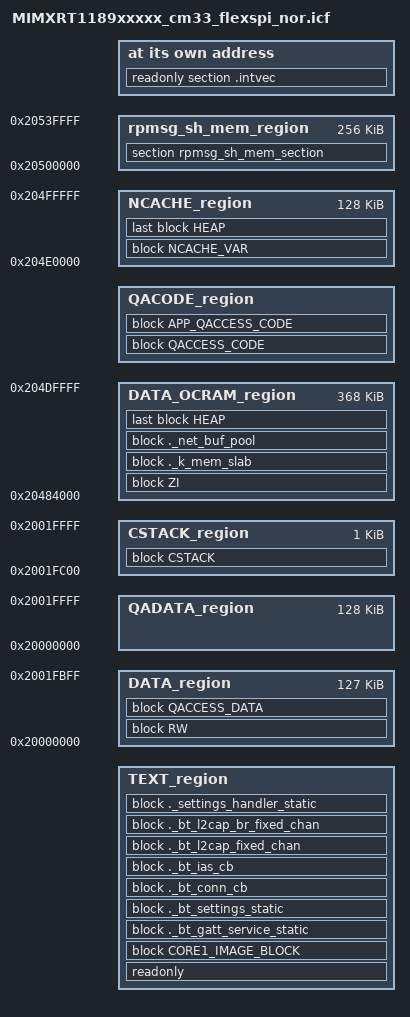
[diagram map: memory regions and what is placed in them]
/*
** ###################################################################
**     Processor:           MIMXRT1189CVM8B_cm33
**     Compiler:            IAR ANSI C/C++ Compiler for ARM
**     Reference manual:    IMXRT1180RM, Rev 2, 12/2022
**     Version:             rev. 0.1, 2021-03-09
**     Build:               b230621
**
**     Abstract:
**         Linker file for the IAR ANSI C/C++ Compiler for ARM
**
**     Copyright 2016 Freescale Semiconductor, Inc.
**     Copyright 2016-2023 NXP
**     SPDX-License-Identifier: BSD-3-Clause
**
**     http:                 www.nxp.com
**     mail:                 support@nxp.com
**
** ###################################################################
*/

/* Board memory map */
define symbol m_code_tcm_start   = 0x0FFE0000;
define symbol m_code_tcm_size    = 0x00020000;
define symbol m_system_tcm_start = 0x20000000;
define symbol m_system_tcm_size  = 0x00020000;
define symbol m_ocram1_start     = 0x20484000;  /* OCRAM1 first 16K access is blocked by TRDC */
define symbol m_ocram1_size      = 0x0007C000;
define symbol m_ocram2_start     = 0x20500000;
define symbol m_ocram2_size      = 0x00040000;

/* CM33 use last 2M bytes space of sdram and hyperram for dual image framework */
define symbol m_sdram_start      = isdefinedsymbol(__dual_image__) ? 0x81E00000 : 0x80000000;
define symbol m_sdram_size       = isdefinedsymbol(__dual_image__) ? 0x00200000 : 0x02000000;
define symbol m_hyperram_start   = isdefinedsymbol(__dual_image__) ? 0x04600000 : 0x04000000;
define symbol m_hyperram_size    = isdefinedsymbol(__dual_image__) ? 0x00200000 : 0x00800000;
define symbol m_flash_start      = 0x28000000;
define symbol m_flash_size       = 0x01000000;

define symbol LITTLEFS_REGION_SIZE = 0x00200000;

define symbol m_core1_image_maximum_size = 0x00040000;

/* General definition */
define symbol app_image_offset         = isdefinedsymbol(__dual_image__) ? 0x0010B000 : 0x0000B000;
define symbol vector_table_size        = 0x00000400;
if (isdefinedsymbol(__stack_size__)) {
  define symbol __size_cstack__        = __stack_size__;
} else {
  define symbol __size_cstack__        = 0x0400;
}

if (isdefinedsymbol(__heap_size__)) {
  define symbol __size_heap__          = __heap_size__;
} else {
  define symbol __size_heap__          = 0x1000;
}

define symbol m_qacode_start           = m_code_tcm_start + (isdefinedsymbol(__ram_vector_table__) ? vector_table_size : 0);
define symbol m_qacode_end             = m_code_tcm_start + m_code_tcm_size - 1;
define symbol m_qadata_start           = m_system_tcm_start;
define symbol m_qadata_end             = m_system_tcm_start + m_system_tcm_size - 1;
define symbol m_ram_vector_table_start = m_code_tcm_start;

/* Target specific definition, code & data allocation */
define symbol m_code_size              = m_flash_size - app_image_offset - LITTLEFS_REGION_SIZE;
define symbol m_data_size              = m_system_tcm_size;
define symbol m_ncache_size            = 0x20000;         /* m_ncache_size must be 2^N */
define symbol m_shmem_size             = m_ocram2_size;   /* m_shmem_size must be 2^N */

define symbol m_ram_vector_table_size  = isdefinedsymbol(__ram_vector_table__) ? vector_table_size : 0;

define symbol m_text_start             = m_flash_start + app_image_offset;
define symbol m_text_end               = m_text_start + m_code_size - 1;
define symbol m_interrupts_start       = m_text_start;

define symbol m_data_start             = m_system_tcm_start;
define symbol m_data_end               = m_data_start + m_data_size - 1;

define symbol m_ncache_start           = m_ocram1_start + m_ocram1_size - m_ncache_size;
define symbol m_ncache_end             = m_ncache_start + m_ncache_size - 1;

define symbol m_data_ocram_start       = m_ocram1_start;
define symbol m_data_ocram_end         = m_ncache_start - 1;

if (isdefinedsymbol(__use_shmem__)) {
  define symbol m_rpmsg_sh_mem_start   = m_ocram2_start;
  define symbol m_rpmsg_sh_mem_end     = m_rpmsg_sh_mem_start + m_shmem_size - 1;
}

/* Exported symbol definition */
define exported symbol __VECTOR_TABLE          = m_interrupts_start;
define exported symbol __VECTOR_RAM            = m_ram_vector_table_start;
define exported symbol __RAM_VECTOR_TABLE_SIZE = m_ram_vector_table_size;
define exported symbol __NCACHE_REGION_START   = m_ncache_start;
define exported symbol __NCACHE_REGION_SIZE    = m_ncache_end - m_ncache_start + 1;
if (isdefinedsymbol(__use_shmem__)) {
  define exported symbol rpmsg_sh_mem_start    = m_rpmsg_sh_mem_start;
  define exported symbol rpmsg_sh_mem_end      = m_rpmsg_sh_mem_end;
  define exported symbol __RPMSG_SH_MEM_START  = m_rpmsg_sh_mem_start;
  define exported symbol __RPMSG_SH_MEM_SIZE   = m_rpmsg_sh_mem_end - m_rpmsg_sh_mem_start + 1;
}

/* NOTE: The last LITTLEFS_REGION_SIZE Flash( in range (m_text_end + 1) ~ (m_text_end + LITTLEFS_REGION_SIZE) ) is reserved for litteFS data */
/*** littleFS configuration Start ***/
define exported symbol EDGEFAST_BT_LITTLEFS_STORAGE_START_ADDRESS = m_text_end + 1;
define exported symbol EDGEFAST_BT_LITTLEFS_STORAGE_SECTOR_SIZE   = 0x1000;  /* 4k flash sector size */
define exported symbol EDGEFAST_BT_LITTLEFS_STORAGE_MAX_SECTORS   = LITTLEFS_REGION_SIZE / EDGEFAST_BT_LITTLEFS_STORAGE_SECTOR_SIZE;
/*** littleFS configuration End ***/

/* Region definition */
define memory mem with size = 4G;
define region TEXT_region        = mem:[from m_text_start to m_text_end];
define region DATA_region        = mem:[from m_data_start to m_data_end-__size_cstack__];
define region CSTACK_region      = mem:[from m_data_end-__size_cstack__+1 to m_data_end];
define region NCACHE_region      = mem:[from m_ncache_start to m_ncache_end];
define region DATA_OCRAM_region  = mem:[from m_data_ocram_start to m_data_ocram_end];
define region QACODE_region      = mem:[from m_qacode_start to m_qacode_end];
define region QADATA_region      = mem:[from m_qadata_start to m_qadata_end];
if (isdefinedsymbol(__use_shmem__)) {
  define region rpmsg_sh_mem_region = mem:[from m_rpmsg_sh_mem_start to m_rpmsg_sh_mem_end];
}

/* Block definition */
define block RW            { readwrite };
define block ZI            { zi };
define block NCACHE_VAR    { section NonCacheable , section NonCacheable.init };
define block QACCESS_CODE  { section CodeQuickAccess };
define block QACCESS_DATA  { section DataQuickAccess };
define block CSTACK    with alignment = 8, size = __size_cstack__   { };
define block HEAP      with alignment = 8, size = __size_heap__     { };
define block CORE1_IMAGE_BLOCK  with alignment = 16, maximum size = m_core1_image_maximum_size  { section  __core1_image };

define block APP_QACCESS_CODE with maximum size = m_code_tcm_size {
  section .text   object fsl_adapter_flexspi_nor_flash.o,
  section .rodata object fsl_adapter_flexspi_nor_flash.o,
  section .text   object mflash_drv.o,
  section .rodata object mflash_drv.o,
  section .text   object fsl_flexspi.o,
  section .rodata object fsl_flexspi.o
};

initialize by copy { readwrite, section .textrw, section DataQuickAccess, section CodeQuickAccess,
  section .text   object fsl_adapter_flexspi_nor_flash.o,
  section .rodata object fsl_adapter_flexspi_nor_flash.o,
  section .text   object mflash_drv.o,
  section .rodata object mflash_drv.o,
  section .text   object fsl_flexspi.o,
  section .rodata object fsl_flexspi.o
};

define block ._bt_gatt_service_static  with fixed order { readonly section ._bt_gatt_service_static*};
define block ._bt_settings_static      with fixed order { readonly section ._bt_settings*};
define block ._bt_conn_cb              with fixed order { readonly section ._bt_conn_cb*};
define block ._bt_ias_cb               with fixed order { readonly section ._bt_ias_cb*};
define block ._bt_l2cap_fixed_chan     with fixed order { readonly section ._bt_l2cap_fixed_chan*};
define block ._bt_l2cap_br_fixed_chan  with fixed order { readonly section ._bt_l2cap_br_fixed_chan*};
define block ._settings_handler_static with fixed order { readonly section ._settings_handler_static*};

define block ._k_mem_slab              with fixed order { readwrite section ._k_mem_slab*};
define block ._net_buf_pool            with fixed order { readwrite section ._net_buf_pool*};

keep { section .flash_area_list, section ._net_buf_pool*, section ._k_mem_slab*, section ._bt*, section ._settings*};

do not initialize  { section .noinit };
if (isdefinedsymbol(__use_shmem__)) {
  do not initialize  { section rpmsg_sh_mem_section };
}

place at address mem: m_interrupts_start    { readonly section .intvec };

place in TEXT_region                        { readonly };
place in TEXT_region                        { block CORE1_IMAGE_BLOCK };
place in TEXT_region                        { block ._bt_gatt_service_static };
place in TEXT_region                        { block ._bt_settings_static };
place in TEXT_region                        { block ._bt_conn_cb };
place in TEXT_region                        { block ._bt_ias_cb };
place in TEXT_region                        { block ._bt_l2cap_fixed_chan };
place in TEXT_region                        { block ._bt_l2cap_br_fixed_chan };
place in TEXT_region                        { block ._settings_handler_static };
place in QACODE_region                      { block QACCESS_CODE };
place in QACODE_region                      { block APP_QACCESS_CODE };
place in DATA_region                        { block RW };
place in DATA_region                        { block QACCESS_DATA };
place in DATA_OCRAM_region                  { block ZI };
place in DATA_OCRAM_region                  { block ._k_mem_slab };
place in DATA_OCRAM_region                  { block ._net_buf_pool };
place in NCACHE_region                      { block NCACHE_VAR };
place in CSTACK_region                      { block CSTACK };
if (isdefinedsymbol(__heap_noncacheable__)) {
  place in NCACHE_region                    { last block HEAP };
} else {
  place in DATA_OCRAM_region                { last block HEAP };
}
if (isdefinedsymbol(__use_shmem__)) {
  place in rpmsg_sh_mem_region              { section rpmsg_sh_mem_section };
}
